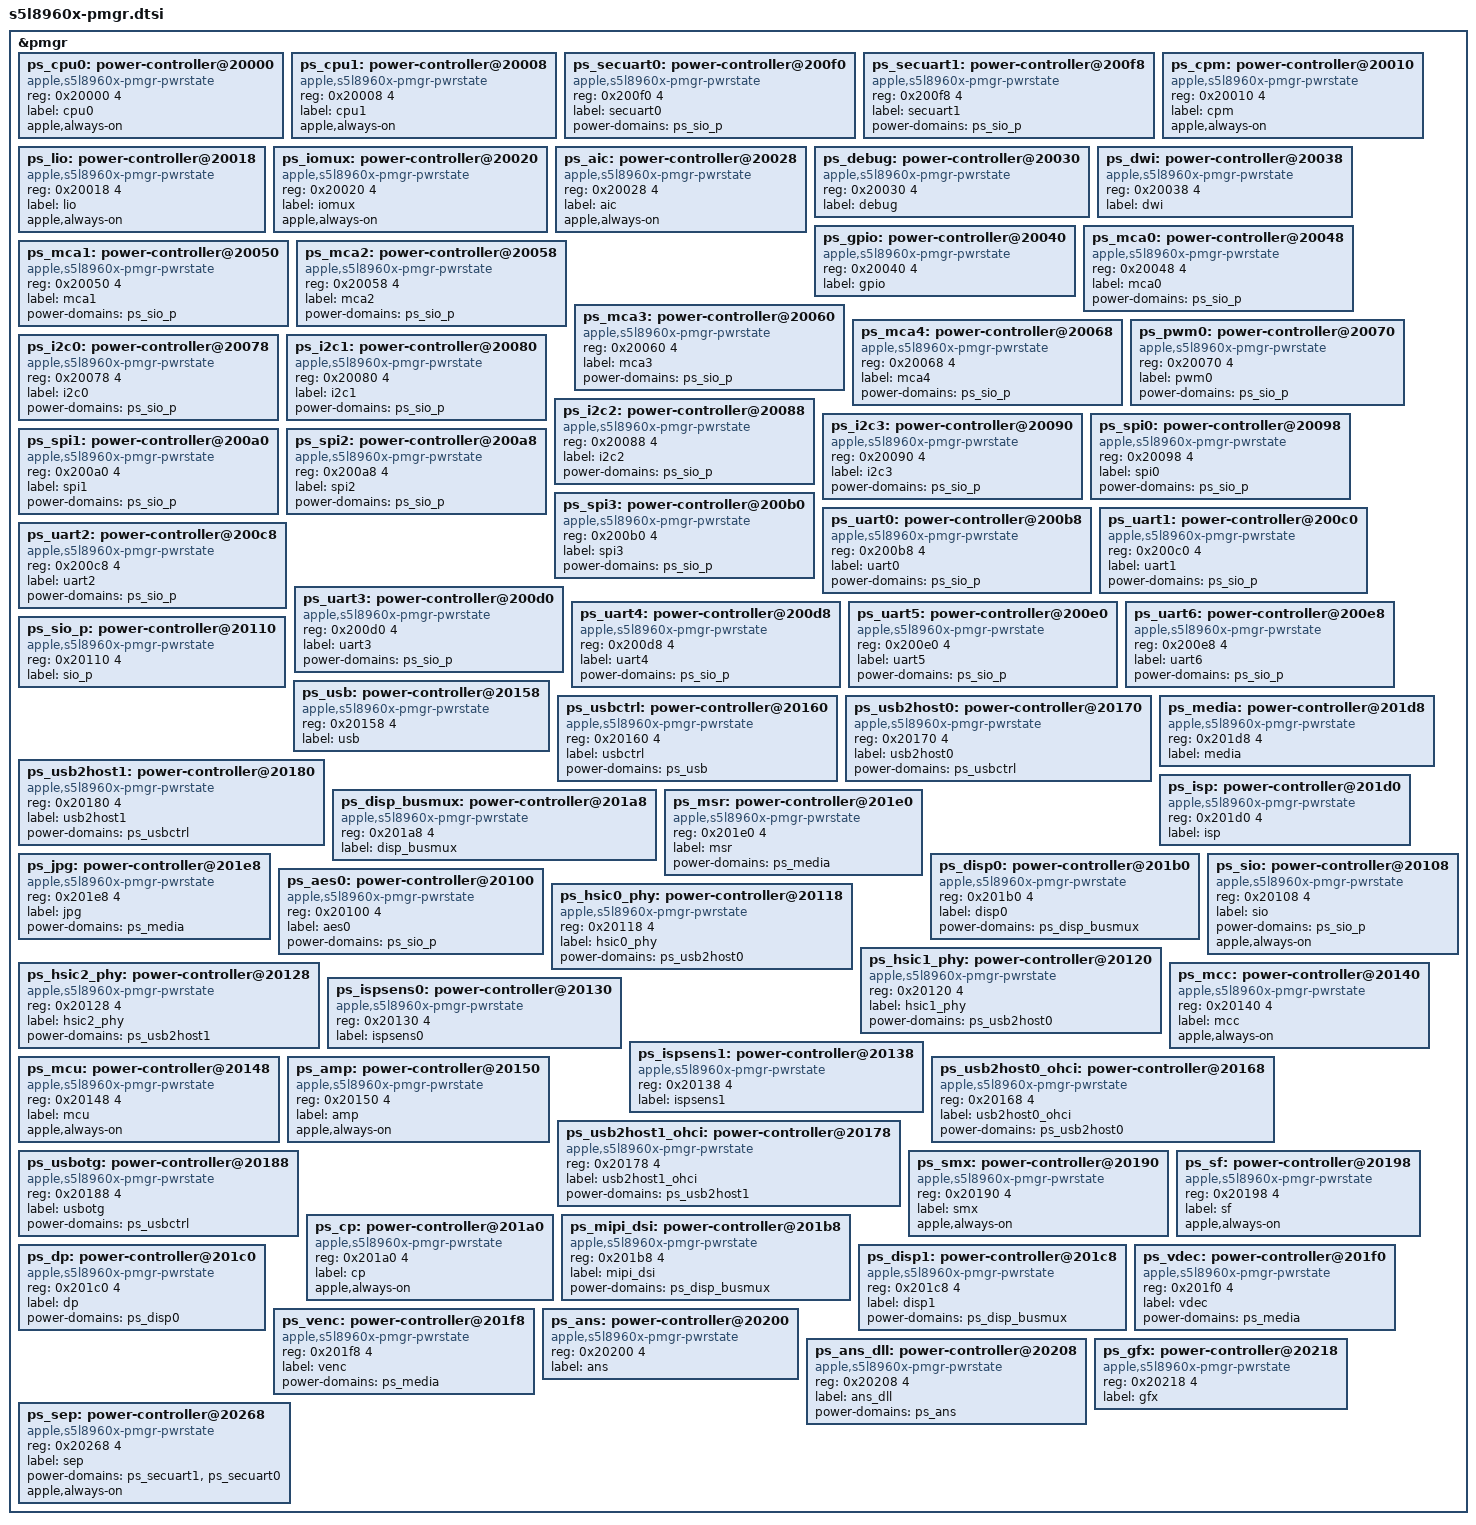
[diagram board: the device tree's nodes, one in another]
// SPDX-License-Identifier: GPL-2.0+ OR MIT
/*
 * PMGR Power domains for the Apple S5L8960X "A7" SoC
 *
 * Copyright (c) 2024 Nick Chan <towinchenmi@gmail.com>
 */

&pmgr {
	ps_cpu0: power-controller@20000 {
		compatible = "apple,s5l8960x-pmgr-pwrstate", "apple,pmgr-pwrstate";
		reg = <0x20000 4>;
		#power-domain-cells = <0>;
		#reset-cells = <0>;
		label = "cpu0";
		apple,always-on; /* Core device */
	};

	ps_cpu1: power-controller@20008 {
		compatible = "apple,s5l8960x-pmgr-pwrstate", "apple,pmgr-pwrstate";
		reg = <0x20008 4>;
		#power-domain-cells = <0>;
		#reset-cells = <0>;
		label = "cpu1";
		apple,always-on; /* Core device */
	};

	ps_secuart0: power-controller@200f0 {
		compatible = "apple,s5l8960x-pmgr-pwrstate", "apple,pmgr-pwrstate";
		reg = <0x200f0 4>;
		#power-domain-cells = <0>;
		#reset-cells = <0>;
		label = "secuart0";
		power-domains = <&ps_sio_p>;
	};

	ps_secuart1: power-controller@200f8 {
		compatible = "apple,s5l8960x-pmgr-pwrstate", "apple,pmgr-pwrstate";
		reg = <0x200f8 4>;
		#power-domain-cells = <0>;
		#reset-cells = <0>;
		label = "secuart1";
		power-domains = <&ps_sio_p>;
	};

	ps_cpm: power-controller@20010 {
		compatible = "apple,s5l8960x-pmgr-pwrstate", "apple,pmgr-pwrstate";
		reg = <0x20010 4>;
		#power-domain-cells = <0>;
		#reset-cells = <0>;
		label = "cpm";
		apple,always-on; /* Core device */
	};

	ps_lio: power-controller@20018 {
		compatible = "apple,s5l8960x-pmgr-pwrstate", "apple,pmgr-pwrstate";
		reg = <0x20018 4>;
		#power-domain-cells = <0>;
		#reset-cells = <0>;
		label = "lio";
		apple,always-on; /* Core device */
	};

	ps_iomux: power-controller@20020 {
		compatible = "apple,s5l8960x-pmgr-pwrstate", "apple,pmgr-pwrstate";
		reg = <0x20020 4>;
		#power-domain-cells = <0>;
		#reset-cells = <0>;
		label = "iomux";
		apple,always-on; /* Core device */
	};

	ps_aic: power-controller@20028 {
		compatible = "apple,s5l8960x-pmgr-pwrstate", "apple,pmgr-pwrstate";
		reg = <0x20028 4>;
		#power-domain-cells = <0>;
		#reset-cells = <0>;
		label = "aic";
		apple,always-on; /* Core device */
	};

	ps_debug: power-controller@20030 {
		compatible = "apple,s5l8960x-pmgr-pwrstate", "apple,pmgr-pwrstate";
		reg = <0x20030 4>;
		#power-domain-cells = <0>;
		#reset-cells = <0>;
		label = "debug";
	};

	ps_dwi: power-controller@20038 {
		compatible = "apple,s5l8960x-pmgr-pwrstate", "apple,pmgr-pwrstate";
		reg = <0x20038 4>;
		#power-domain-cells = <0>;
		#reset-cells = <0>;
		label = "dwi";
	};

	ps_gpio: power-controller@20040 {
		compatible = "apple,s5l8960x-pmgr-pwrstate", "apple,pmgr-pwrstate";
		reg = <0x20040 4>;
		#power-domain-cells = <0>;
		#reset-cells = <0>;
		label = "gpio";
	};

	ps_mca0: power-controller@20048 {
		compatible = "apple,s5l8960x-pmgr-pwrstate", "apple,pmgr-pwrstate";
		reg = <0x20048 4>;
		#power-domain-cells = <0>;
		#reset-cells = <0>;
		label = "mca0";
		power-domains = <&ps_sio_p>;
	};

	ps_mca1: power-controller@20050 {
		compatible = "apple,s5l8960x-pmgr-pwrstate", "apple,pmgr-pwrstate";
		reg = <0x20050 4>;
		#power-domain-cells = <0>;
		#reset-cells = <0>;
		label = "mca1";
		power-domains = <&ps_sio_p>;
	};

	ps_mca2: power-controller@20058 {
		compatible = "apple,s5l8960x-pmgr-pwrstate", "apple,pmgr-pwrstate";
		reg = <0x20058 4>;
		#power-domain-cells = <0>;
		#reset-cells = <0>;
		label = "mca2";
		power-domains = <&ps_sio_p>;
	};

	ps_mca3: power-controller@20060 {
		compatible = "apple,s5l8960x-pmgr-pwrstate", "apple,pmgr-pwrstate";
		reg = <0x20060 4>;
		#power-domain-cells = <0>;
		#reset-cells = <0>;
		label = "mca3";
		power-domains = <&ps_sio_p>;
	};

	ps_mca4: power-controller@20068 {
		compatible = "apple,s5l8960x-pmgr-pwrstate", "apple,pmgr-pwrstate";
		reg = <0x20068 4>;
		#power-domain-cells = <0>;
		#reset-cells = <0>;
		label = "mca4";
		power-domains = <&ps_sio_p>;
	};

	ps_pwm0: power-controller@20070 {
		compatible = "apple,s5l8960x-pmgr-pwrstate", "apple,pmgr-pwrstate";
		reg = <0x20070 4>;
		#power-domain-cells = <0>;
		#reset-cells = <0>;
		label = "pwm0";
		power-domains = <&ps_sio_p>;
	};

	ps_i2c0: power-controller@20078 {
		compatible = "apple,s5l8960x-pmgr-pwrstate", "apple,pmgr-pwrstate";
		reg = <0x20078 4>;
		#power-domain-cells = <0>;
		#reset-cells = <0>;
		label = "i2c0";
		power-domains = <&ps_sio_p>;
	};

	ps_i2c1: power-controller@20080 {
		compatible = "apple,s5l8960x-pmgr-pwrstate", "apple,pmgr-pwrstate";
		reg = <0x20080 4>;
		#power-domain-cells = <0>;
		#reset-cells = <0>;
		label = "i2c1";
		power-domains = <&ps_sio_p>;
	};

	ps_i2c2: power-controller@20088 {
		compatible = "apple,s5l8960x-pmgr-pwrstate", "apple,pmgr-pwrstate";
		reg = <0x20088 4>;
		#power-domain-cells = <0>;
		#reset-cells = <0>;
		label = "i2c2";
		power-domains = <&ps_sio_p>;
	};

	ps_i2c3: power-controller@20090 {
		compatible = "apple,s5l8960x-pmgr-pwrstate", "apple,pmgr-pwrstate";
		reg = <0x20090 4>;
		#power-domain-cells = <0>;
		#reset-cells = <0>;
		label = "i2c3";
		power-domains = <&ps_sio_p>;
	};

	ps_spi0: power-controller@20098 {
		compatible = "apple,s5l8960x-pmgr-pwrstate", "apple,pmgr-pwrstate";
		reg = <0x20098 4>;
		#power-domain-cells = <0>;
		#reset-cells = <0>;
		label = "spi0";
		power-domains = <&ps_sio_p>;
	};

	ps_spi1: power-controller@200a0 {
		compatible = "apple,s5l8960x-pmgr-pwrstate", "apple,pmgr-pwrstate";
		reg = <0x200a0 4>;
		#power-domain-cells = <0>;
		#reset-cells = <0>;
		label = "spi1";
		power-domains = <&ps_sio_p>;
	};

	ps_spi2: power-controller@200a8 {
		compatible = "apple,s5l8960x-pmgr-pwrstate", "apple,pmgr-pwrstate";
		reg = <0x200a8 4>;
		#power-domain-cells = <0>;
		#reset-cells = <0>;
		label = "spi2";
		power-domains = <&ps_sio_p>;
	};

	ps_spi3: power-controller@200b0 {
		compatible = "apple,s5l8960x-pmgr-pwrstate", "apple,pmgr-pwrstate";
		reg = <0x200b0 4>;
		#power-domain-cells = <0>;
		#reset-cells = <0>;
		label = "spi3";
		power-domains = <&ps_sio_p>;
	};

	ps_uart0: power-controller@200b8 {
		compatible = "apple,s5l8960x-pmgr-pwrstate", "apple,pmgr-pwrstate";
		reg = <0x200b8 4>;
		#power-domain-cells = <0>;
		#reset-cells = <0>;
		label = "uart0";
		power-domains = <&ps_sio_p>;
	};

	ps_uart1: power-controller@200c0 {
		compatible = "apple,s5l8960x-pmgr-pwrstate", "apple,pmgr-pwrstate";
		reg = <0x200c0 4>;
		#power-domain-cells = <0>;
		#reset-cells = <0>;
		label = "uart1";
		power-domains = <&ps_sio_p>;
	};

	ps_uart2: power-controller@200c8 {
		compatible = "apple,s5l8960x-pmgr-pwrstate", "apple,pmgr-pwrstate";
		reg = <0x200c8 4>;
		#power-domain-cells = <0>;
		#reset-cells = <0>;
		label = "uart2";
		power-domains = <&ps_sio_p>;
	};

	ps_uart3: power-controller@200d0 {
		compatible = "apple,s5l8960x-pmgr-pwrstate", "apple,pmgr-pwrstate";
		reg = <0x200d0 4>;
		#power-domain-cells = <0>;
		#reset-cells = <0>;
		label = "uart3";
		power-domains = <&ps_sio_p>;
	};

	ps_uart4: power-controller@200d8 {
		compatible = "apple,s5l8960x-pmgr-pwrstate", "apple,pmgr-pwrstate";
		reg = <0x200d8 4>;
		#power-domain-cells = <0>;
		#reset-cells = <0>;
		label = "uart4";
		power-domains = <&ps_sio_p>;
	};

	ps_uart5: power-controller@200e0 {
		compatible = "apple,s5l8960x-pmgr-pwrstate", "apple,pmgr-pwrstate";
		reg = <0x200e0 4>;
		#power-domain-cells = <0>;
		#reset-cells = <0>;
		label = "uart5";
		power-domains = <&ps_sio_p>;
	};

	ps_uart6: power-controller@200e8 {
		compatible = "apple,s5l8960x-pmgr-pwrstate", "apple,pmgr-pwrstate";
		reg = <0x200e8 4>;
		#power-domain-cells = <0>;
		#reset-cells = <0>;
		label = "uart6";
		power-domains = <&ps_sio_p>;
	};

	ps_sio_p: power-controller@20110 {
		compatible = "apple,s5l8960x-pmgr-pwrstate", "apple,pmgr-pwrstate";
		reg = <0x20110 4>;
		#power-domain-cells = <0>;
		#reset-cells = <0>;
		label = "sio_p";
	};

	ps_usb: power-controller@20158 {
		compatible = "apple,s5l8960x-pmgr-pwrstate", "apple,pmgr-pwrstate";
		reg = <0x20158 4>;
		#power-domain-cells = <0>;
		#reset-cells = <0>;
		label = "usb";
	};

	ps_usbctrl: power-controller@20160 {
		compatible = "apple,s5l8960x-pmgr-pwrstate", "apple,pmgr-pwrstate";
		reg = <0x20160 4>;
		#power-domain-cells = <0>;
		#reset-cells = <0>;
		label = "usbctrl";
		power-domains = <&ps_usb>;
	};

	ps_usb2host0: power-controller@20170 {
		compatible = "apple,s5l8960x-pmgr-pwrstate", "apple,pmgr-pwrstate";
		reg = <0x20170 4>;
		#power-domain-cells = <0>;
		#reset-cells = <0>;
		label = "usb2host0";
		power-domains = <&ps_usbctrl>;
	};

	ps_usb2host1: power-controller@20180 {
		compatible = "apple,s5l8960x-pmgr-pwrstate", "apple,pmgr-pwrstate";
		reg = <0x20180 4>;
		#power-domain-cells = <0>;
		#reset-cells = <0>;
		label = "usb2host1";
		power-domains = <&ps_usbctrl>;
	};

	ps_disp_busmux: power-controller@201a8 {
		compatible = "apple,s5l8960x-pmgr-pwrstate", "apple,pmgr-pwrstate";
		reg = <0x201a8 4>;
		#power-domain-cells = <0>;
		#reset-cells = <0>;
		label = "disp_busmux";
	};

	ps_media: power-controller@201d8 {
		compatible = "apple,s5l8960x-pmgr-pwrstate", "apple,pmgr-pwrstate";
		reg = <0x201d8 4>;
		#power-domain-cells = <0>;
		#reset-cells = <0>;
		label = "media";
	};

	ps_isp: power-controller@201d0 {
		compatible = "apple,s5l8960x-pmgr-pwrstate", "apple,pmgr-pwrstate";
		reg = <0x201d0 4>;
		#power-domain-cells = <0>;
		#reset-cells = <0>;
		label = "isp";
	};

	ps_msr: power-controller@201e0 {
		compatible = "apple,s5l8960x-pmgr-pwrstate", "apple,pmgr-pwrstate";
		reg = <0x201e0 4>;
		#power-domain-cells = <0>;
		#reset-cells = <0>;
		label = "msr";
		power-domains = <&ps_media>;
	};

	ps_jpg: power-controller@201e8 {
		compatible = "apple,s5l8960x-pmgr-pwrstate", "apple,pmgr-pwrstate";
		reg = <0x201e8 4>;
		#power-domain-cells = <0>;
		#reset-cells = <0>;
		label = "jpg";
		power-domains = <&ps_media>;
	};

	ps_disp0: power-controller@201b0 {
		compatible = "apple,s5l8960x-pmgr-pwrstate", "apple,pmgr-pwrstate";
		reg = <0x201b0 4>;
		#power-domain-cells = <0>;
		#reset-cells = <0>;
		label = "disp0";
		power-domains = <&ps_disp_busmux>;
	};

	ps_aes0: power-controller@20100 {
		compatible = "apple,s5l8960x-pmgr-pwrstate", "apple,pmgr-pwrstate";
		reg = <0x20100 4>;
		#power-domain-cells = <0>;
		#reset-cells = <0>;
		label = "aes0";
		power-domains = <&ps_sio_p>;
	};

	ps_sio: power-controller@20108 {
		compatible = "apple,s5l8960x-pmgr-pwrstate", "apple,pmgr-pwrstate";
		reg = <0x20108 4>;
		#power-domain-cells = <0>;
		#reset-cells = <0>;
		label = "sio";
		power-domains = <&ps_sio_p>;
		apple,always-on; /* Core device */
	};

	ps_hsic0_phy: power-controller@20118 {
		compatible = "apple,s5l8960x-pmgr-pwrstate", "apple,pmgr-pwrstate";
		reg = <0x20118 4>;
		#power-domain-cells = <0>;
		#reset-cells = <0>;
		label = "hsic0_phy";
		power-domains = <&ps_usb2host0>;
	};

	ps_hsic1_phy: power-controller@20120 {
		compatible = "apple,s5l8960x-pmgr-pwrstate", "apple,pmgr-pwrstate";
		reg = <0x20120 4>;
		#power-domain-cells = <0>;
		#reset-cells = <0>;
		label = "hsic1_phy";
		power-domains = <&ps_usb2host0>;
	};

	ps_hsic2_phy: power-controller@20128 {
		compatible = "apple,s5l8960x-pmgr-pwrstate", "apple,pmgr-pwrstate";
		reg = <0x20128 4>;
		#power-domain-cells = <0>;
		#reset-cells = <0>;
		label = "hsic2_phy";
		power-domains = <&ps_usb2host1>;
	};

	ps_ispsens0: power-controller@20130 {
		compatible = "apple,s5l8960x-pmgr-pwrstate", "apple,pmgr-pwrstate";
		reg = <0x20130 4>;
		#power-domain-cells = <0>;
		#reset-cells = <0>;
		label = "ispsens0";
	};

	ps_ispsens1: power-controller@20138 {
		compatible = "apple,s5l8960x-pmgr-pwrstate", "apple,pmgr-pwrstate";
		reg = <0x20138 4>;
		#power-domain-cells = <0>;
		#reset-cells = <0>;
		label = "ispsens1";
	};

	ps_mcc: power-controller@20140 {
		compatible = "apple,s5l8960x-pmgr-pwrstate", "apple,pmgr-pwrstate";
		reg = <0x20140 4>;
		#power-domain-cells = <0>;
		#reset-cells = <0>;
		label = "mcc";
		apple,always-on; /* Core device */
	};

	ps_mcu: power-controller@20148 {
		compatible = "apple,s5l8960x-pmgr-pwrstate", "apple,pmgr-pwrstate";
		reg = <0x20148 4>;
		#power-domain-cells = <0>;
		#reset-cells = <0>;
		label = "mcu";
		apple,always-on; /* Core device */
	};

	ps_amp: power-controller@20150 {
		compatible = "apple,s5l8960x-pmgr-pwrstate", "apple,pmgr-pwrstate";
		reg = <0x20150 4>;
		#power-domain-cells = <0>;
		#reset-cells = <0>;
		label = "amp";
		apple,always-on; /* Core device */
	};

	ps_usb2host0_ohci: power-controller@20168 {
		compatible = "apple,s5l8960x-pmgr-pwrstate", "apple,pmgr-pwrstate";
		reg = <0x20168 4>;
		#power-domain-cells = <0>;
		#reset-cells = <0>;
		label = "usb2host0_ohci";
		power-domains = <&ps_usb2host0>;
	};

	ps_usb2host1_ohci: power-controller@20178 {
		compatible = "apple,s5l8960x-pmgr-pwrstate", "apple,pmgr-pwrstate";
		reg = <0x20178 4>;
		#power-domain-cells = <0>;
		#reset-cells = <0>;
		label = "usb2host1_ohci";
		power-domains = <&ps_usb2host1>;
	};

	ps_usbotg: power-controller@20188 {
		compatible = "apple,s5l8960x-pmgr-pwrstate", "apple,pmgr-pwrstate";
		reg = <0x20188 4>;
		#power-domain-cells = <0>;
		#reset-cells = <0>;
		label = "usbotg";
		power-domains = <&ps_usbctrl>;
	};

	ps_smx: power-controller@20190 {
		compatible = "apple,s5l8960x-pmgr-pwrstate", "apple,pmgr-pwrstate";
		reg = <0x20190 4>;
		#power-domain-cells = <0>;
		#reset-cells = <0>;
		label = "smx";
		apple,always-on; /* Apple fabric, critical block */
	};

	ps_sf: power-controller@20198 {
		compatible = "apple,s5l8960x-pmgr-pwrstate", "apple,pmgr-pwrstate";
		reg = <0x20198 4>;
		#power-domain-cells = <0>;
		#reset-cells = <0>;
		label = "sf";
		apple,always-on; /* Apple fabric, critical block */
	};

	ps_cp: power-controller@201a0 {
		compatible = "apple,s5l8960x-pmgr-pwrstate", "apple,pmgr-pwrstate";
		reg = <0x201a0 4>;
		#power-domain-cells = <0>;
		#reset-cells = <0>;
		label = "cp";
		apple,always-on; /* Core device */
	};

	ps_mipi_dsi: power-controller@201b8 {
		compatible = "apple,s5l8960x-pmgr-pwrstate", "apple,pmgr-pwrstate";
		reg = <0x201b8 4>;
		#power-domain-cells = <0>;
		#reset-cells = <0>;
		label = "mipi_dsi";
		power-domains = <&ps_disp_busmux>;
	};

	ps_dp: power-controller@201c0 {
		compatible = "apple,s5l8960x-pmgr-pwrstate", "apple,pmgr-pwrstate";
		reg = <0x201c0 4>;
		#power-domain-cells = <0>;
		#reset-cells = <0>;
		label = "dp";
		power-domains = <&ps_disp0>;
	};

	ps_disp1: power-controller@201c8 {
		compatible = "apple,s5l8960x-pmgr-pwrstate", "apple,pmgr-pwrstate";
		reg = <0x201c8 4>;
		#power-domain-cells = <0>;
		#reset-cells = <0>;
		label = "disp1";
		power-domains = <&ps_disp_busmux>;
	};

	ps_vdec: power-controller@201f0 {
		compatible = "apple,s5l8960x-pmgr-pwrstate", "apple,pmgr-pwrstate";
		reg = <0x201f0 4>;
		#power-domain-cells = <0>;
		#reset-cells = <0>;
		label = "vdec";
		power-domains = <&ps_media>;
	};

	ps_venc: power-controller@201f8 {
		compatible = "apple,s5l8960x-pmgr-pwrstate", "apple,pmgr-pwrstate";
		reg = <0x201f8 4>;
		#power-domain-cells = <0>;
		#reset-cells = <0>;
		label = "venc";
		power-domains = <&ps_media>;
	};

	ps_ans: power-controller@20200 {
		compatible = "apple,s5l8960x-pmgr-pwrstate", "apple,pmgr-pwrstate";
		reg = <0x20200 4>;
		#power-domain-cells = <0>;
		#reset-cells = <0>;
		label = "ans";
	};

	ps_ans_dll: power-controller@20208 {
		compatible = "apple,s5l8960x-pmgr-pwrstate", "apple,pmgr-pwrstate";
		reg = <0x20208 4>;
		#power-domain-cells = <0>;
		#reset-cells = <0>;
		label = "ans_dll";
		power-domains = <&ps_ans>;
	};

	ps_gfx: power-controller@20218 {
		compatible = "apple,s5l8960x-pmgr-pwrstate", "apple,pmgr-pwrstate";
		reg = <0x20218 4>;
		#power-domain-cells = <0>;
		#reset-cells = <0>;
		label = "gfx";
	};

	ps_sep: power-controller@20268 {
		compatible = "apple,s5l8960x-pmgr-pwrstate", "apple,pmgr-pwrstate";
		reg = <0x20268 4>;
		#power-domain-cells = <0>;
		#reset-cells = <0>;
		label = "sep";
		power-domains = <&ps_secuart1>, <&ps_secuart0>;
		apple,always-on; /* Locked on */
	};
};
